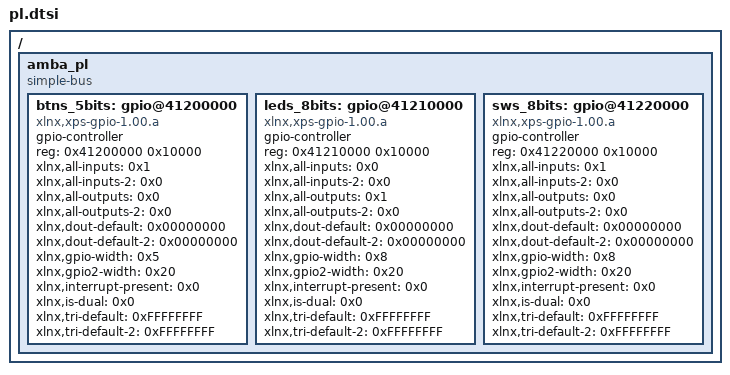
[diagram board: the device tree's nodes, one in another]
/*
 * CAUTION: This file is automatically generated by Xilinx.
 * Version: HSI 
 * Today is: Mon Nov 24 12:27:32 2014
*/


/ {
	amba_pl: amba_pl {
		#address-cells = <1>;
		#size-cells = <1>;
		compatible = "simple-bus";
		ranges ;
		btns_5bits: gpio@41200000 {
			#gpio-cells = <2>;
			compatible = "xlnx,xps-gpio-1.00.a";
			gpio-controller ;
			reg = <0x41200000 0x10000>;
			xlnx,all-inputs = <0x1>;
			xlnx,all-inputs-2 = <0x0>;
			xlnx,all-outputs = <0x0>;
			xlnx,all-outputs-2 = <0x0>;
			xlnx,dout-default = <0x00000000>;
			xlnx,dout-default-2 = <0x00000000>;
			xlnx,gpio-width = <0x5>;
			xlnx,gpio2-width = <0x20>;
			xlnx,interrupt-present = <0x0>;
			xlnx,is-dual = <0x0>;
			xlnx,tri-default = <0xFFFFFFFF>;
			xlnx,tri-default-2 = <0xFFFFFFFF>;
		};
		leds_8bits: gpio@41210000 {
			#gpio-cells = <2>;
			compatible = "xlnx,xps-gpio-1.00.a";
			gpio-controller ;
			reg = <0x41210000 0x10000>;
			xlnx,all-inputs = <0x0>;
			xlnx,all-inputs-2 = <0x0>;
			xlnx,all-outputs = <0x1>;
			xlnx,all-outputs-2 = <0x0>;
			xlnx,dout-default = <0x00000000>;
			xlnx,dout-default-2 = <0x00000000>;
			xlnx,gpio-width = <0x8>;
			xlnx,gpio2-width = <0x20>;
			xlnx,interrupt-present = <0x0>;
			xlnx,is-dual = <0x0>;
			xlnx,tri-default = <0xFFFFFFFF>;
			xlnx,tri-default-2 = <0xFFFFFFFF>;
		};
		sws_8bits: gpio@41220000 {
			#gpio-cells = <2>;
			compatible = "xlnx,xps-gpio-1.00.a";
			gpio-controller ;
			reg = <0x41220000 0x10000>;
			xlnx,all-inputs = <0x1>;
			xlnx,all-inputs-2 = <0x0>;
			xlnx,all-outputs = <0x0>;
			xlnx,all-outputs-2 = <0x0>;
			xlnx,dout-default = <0x00000000>;
			xlnx,dout-default-2 = <0x00000000>;
			xlnx,gpio-width = <0x8>;
			xlnx,gpio2-width = <0x20>;
			xlnx,interrupt-present = <0x0>;
			xlnx,is-dual = <0x0>;
			xlnx,tri-default = <0xFFFFFFFF>;
			xlnx,tri-default-2 = <0xFFFFFFFF>;
		};
	};
};
